# bao1x_peri register map
Vendor: baochip
Registers are 32-bit, read-write, reset 0x0 unless marked. A register's access mark holds for its fields unless they carry their own. Offsets are from the block's base; [hi:lo] are bit positions; {n}, {i} and the like mark numbered series; <NAME> marks a mode.

## SENSORC
Base 0x40053000
0x00 SFR_VDMASK0 — See `sensorc.sv#L63 <https://github.com/baochip/baochip-1x/blob/main/rtl/modules /sec/rtl/sensorc.sv#L63>`__ (line numbers are approximate)
  [7:0] cr_vdmask0 — cr_vdmask0 read/write control register
0x04 SFR_VDMASK1 — See `sensorc.sv#L64 <https://github.com/baochip/baochip-1x/blob/main/rtl/modules /sec/rtl/sensorc.sv#L64>`__ (line numbers are approximate)
  [7:0] cr_vdmask1 — cr_vdmask1 read/write control register
0x08 SFR_VDSR — See `sensorc.sv#L65 <https://github.com/baochip/baochip-1x/blob/main/rtl/modules /sec/rtl/sensorc.sv#L65>`__ (line numbers are approximate)
  [7:0] vdflag — vdflag read only status register
0x0C SFR_VDFR — See `sensorc.sv#L66 <https://github.com/baochip/baochip-1x/blob/main/rtl/modules /sec/rtl/sensorc.sv#L66>`__ (line numbers are approximate)
  [7:0] vdflag — vdflag flag register. `1` means event happened, write back `1` in respective bit position to clear the flag
0x10 SFR_LDMASK — See `sensorc.sv#L68 <https://github.com/baochip/baochip-1x/blob/main/rtl/modules /sec/rtl/sensorc.sv#L68>`__ (line numbers are approximate)
  [3:0] cr_ldmask — cr_ldmask read/write control register
0x14 SFR_LDSR — See `sensorc.sv#L69 <https://github.com/baochip/baochip-1x/blob/main/rtl/modules /sec/rtl/sensorc.sv#L69>`__ (line numbers are approximate)
  [3:0] sr_ldsr — sr_ldsr read only status register
0x18 SFR_LDCFG — See `sensorc.sv#L70 <https://github.com/baochip/baochip-1x/blob/main/rtl/modules /sec/rtl/sensorc.sv#L70>`__ (line numbers are approximate)
  [3:0] sfr_ldcfg — sfr_ldcfg read/write control register
{0x20+4i} SFR_VDCFG_CR_VDCFG{i} (i=0..7) — See `sensorc.sv#L72 <https://github.com/baochip/baochip-1x/blob/main/rtl/modules /sec/rtl/sensorc.sv#L72>`__ (line numbers are approximate)
  [3:0] cr_vdcfg{i} — cr_vdcfg read/write control register
0x40 SFR_VDIP_ENA — See `sensorc.sv#L74 <https://github.com/baochip/baochip-1x/blob/main/rtl/modules /sec/rtl/sensorc.sv#L74>`__ (line numbers are approximate)
  [5:0] vdena — vdena read/write control register
0x44 SFR_VDIP_TEST — See `sensorc.sv#L75 <https://github.com/baochip/baochip-1x/blob/main/rtl/modules /sec/rtl/sensorc.sv#L75>`__ (line numbers are approximate)
  [7:0] vdtst — vdtst read/write control register
0x48 SFR_LDIP_TEST — See `sensorc.sv#L77 <https://github.com/baochip/baochip-1x/blob/main/rtl/modules /sec/rtl/sensorc.sv#L77>`__ (line numbers are approximate)
  [3:0] ldtst — ldtst read/write control register
0x4C SFR_LDIP_FD — See `sensorc.sv#L78 <https://github.com/baochip/baochip-1x/blob/main/rtl/modules /sec/rtl/sensorc.sv#L78>`__ (line numbers are approximate)
  [15:0] sfr_ldip_fd — sfr_ldip_fd read/write control register

## AOBUREG
Base 0x40065000
{0x0+4i} SFR_BUREG_CR_BUREGS{i} (i=0..7) — See `aobureg.sv#L33 <https://github.com/baochip/baochip-1x/blob/main/rtl/modules /ao/rtl/aobureg.sv#L33>`__ (line numbers are approximate)
  [31:0] cr_buregs{i} — cr_buregs read/write control register

## DKPC
Base 0x40064000
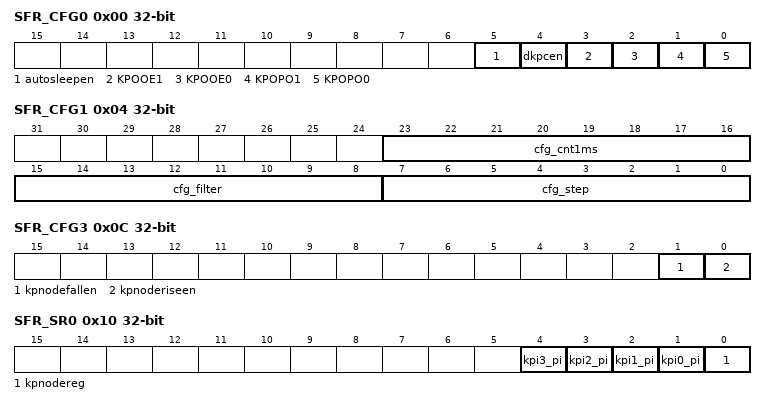
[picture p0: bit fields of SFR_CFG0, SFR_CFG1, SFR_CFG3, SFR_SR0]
0x00 SFR_CFG0 — See `dkpc.sv#L167 <https://github.com/baochip/baochip-1x/blob/main/rtl/modules/a o/rtl/dkpc.sv#L167>`__ (line numbers are approximate)
  [5] autosleepen — autosleepen read/write control register
  [4] dkpcen — dkpcen read/write control register
  [3] KPOOE1 — KPOOE1 read/write control register
  [2] KPOOE0 — KPOOE0 read/write control register
  [1] KPOPO1 — KPOPO1 read/write control register
  [0] KPOPO0 — KPOPO0 read/write control register
0x04 SFR_CFG1 — See `dkpc.sv#L168 <https://github.com/baochip/baochip-1x/blob/main/rtl/modules/a o/rtl/dkpc.sv#L168>`__ (line numbers are approximate)
  [23:16] cfg_cnt1ms — cfg_cnt1ms read/write control register
  [15:8] cfg_filter — cfg_filter read/write control register
  [7:0] cfg_step — cfg_step read/write control register
0x08 SFR_CFG2 — See `dkpc.sv#L169 <https://github.com/baochip/baochip-1x/blob/main/rtl/modules/a o/rtl/dkpc.sv#L169>`__ (line numbers are approximate)
  [31:0] cfg_cnt — cfg_cnt read/write control register
0x0C SFR_CFG3 — See `dkpc.sv#L170 <https://github.com/baochip/baochip-1x/blob/main/rtl/modules/a o/rtl/dkpc.sv#L170>`__ (line numbers are approximate)
  [1] kpnodefallen — kpnodefallen read/write control register
  [0] kpnoderiseen — kpnoderiseen read/write control register
0x10 SFR_SR0 — See `dkpc.sv#L173 <https://github.com/baochip/baochip-1x/blob/main/rtl/modules/a o/rtl/dkpc.sv#L173>`__ (line numbers are approximate)
  [n+1] kpi{n}_pi (n=0..3) — kpi[{n}].pi read only status register
  [0] kpnodereg — kpnodereg read only status register
0x14 SFR_SR1 — See `dkpc.sv#L174 <https://github.com/baochip/baochip-1x/blob/main/rtl/modules/a o/rtl/dkpc.sv#L174>`__ (line numbers are approximate)
  [0] sfr_sr1 — sfr_sr1 read only status register
0x30 SFR_CFG4 — See `dkpc.sv#L171 <https://github.com/baochip/baochip-1x/blob/main/rtl/modules/a o/rtl/dkpc.sv#L171>`__ (line numbers are approximate)
  [15:0] sfr_cfg4 — sfr_cfg4 read/write control register
